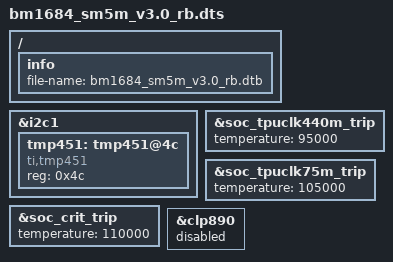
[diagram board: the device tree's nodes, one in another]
#include "bm1684.dtsi"
#include "bm1684_mm_12g.dtsi"
#include "bm1684_sm5_rb.dtsi"

&i2c1 {
	/delete-node/ tmp451@6b;

	tmp451: tmp451@4c {
		compatible = "ti,tmp451";
		reg = <0x4c>;
		#thermal-sensor-cells = <1>;
	};
};

&soc_tpuclk440m_trip {
	temperature = <95000>;
};

&soc_tpuclk75m_trip {
	temperature = <105000>;
};

&soc_crit_trip {
	temperature = <110000>;
};

&clp890 {
	status = "disabled";
};

/ {
	info {
		file-name = "bm1684_sm5m_v3.0_rb.dtb";
	};
};
